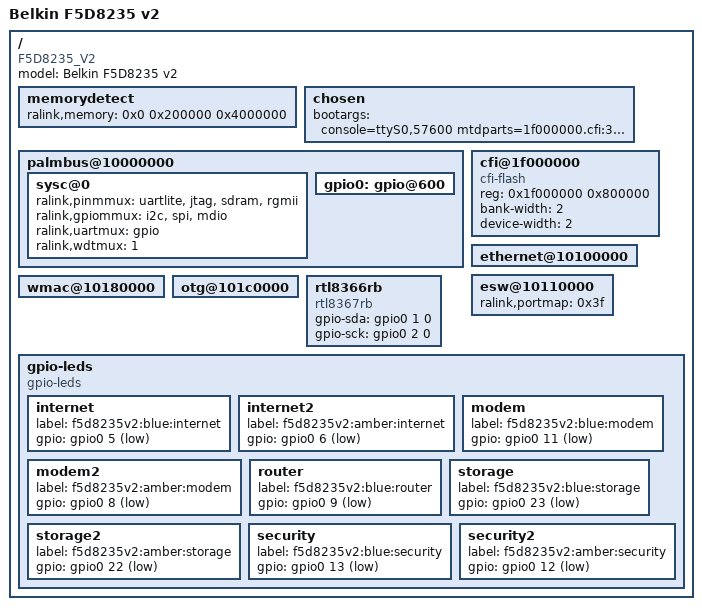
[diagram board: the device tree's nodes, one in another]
/dts-v1/;

/include/ "rt3050.dtsi"

/ {
	#address-cells = <1>;
	#size-cells = <1>;
	compatible = "F5D8235_V2", "ralink,rt3052-soc";
	model = "Belkin F5D8235 v2";

	memorydetect {
		ralink,memory = <0x0 0x200000 0x4000000>;
	};


	chosen {
		bootargs = "console=ttyS0,57600 mtdparts=1f000000.cfi:320k(u-boot)ro,7744k(firmware),64k(nvram),64k(factory)";
	};

	palmbus@10000000 {
		sysc@0 {
			ralink,pinmmux = "uartlite", "jtag", "sdram", "rgmii";
			ralink,gpiommux = "i2c", "spi", "mdio";
			ralink,uartmux = "gpio";
			ralink,wdtmux = <1>;
		};

		gpio0: gpio@600 {
			status = "okay";
		};

	};

	cfi@1f000000 {
		compatible = "cfi-flash";
		reg = <0x1f000000 0x800000>;

		bank-width = <2>;
		device-width = <2>;
		#address-cells = <1>;
		#size-cells = <1>;
	};

	ethernet@10100000 {
		status = "okay";
	};

	esw@10110000 {
		status = "okay";
		ralink,portmap = <0x3f>;
	};

	wmac@10180000 {
		status = "okay";
	};

	otg@101c0000 {
		status = "okay";
	};

	rtl8366rb {
		compatible = "rtl8367rb";
		gpio-sda = <&gpio0 1 0>;
		gpio-sck = <&gpio0 2 0>;
	};
	
	gpio-leds {
		compatible = "gpio-leds";
		internet {
			label = "f5d8235v2:blue:internet";
			gpio = <&gpio0 5 1>;
		};
		internet2 {
			label = "f5d8235v2:amber:internet";
			gpio = <&gpio0 6 1>;
		};
		modem {
			label = "f5d8235v2:blue:modem";
			gpio = <&gpio0 11 1>;
		};
		modem2 {
			label = "f5d8235v2:amber:modem";
			gpio = <&gpio0 8 1>;
		};
		router {
			label = "f5d8235v2:blue:router";
			gpio = <&gpio0 9 1>;
		};
		storage {
			label = "f5d8235v2:blue:storage";
			gpio = <&gpio0 23 1>;
		};
		storage2 {
			label = "f5d8235v2:amber:storage";
			gpio = <&gpio0 22 1>;
		};
		security {
			label = "f5d8235v2:blue:security";
			gpio = <&gpio0 13 1>;
		};
		security2 {
			label = "f5d8235v2:amber:security";
			gpio = <&gpio0 12 1>;
		};
	};
};
